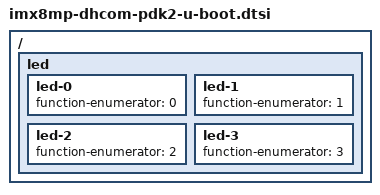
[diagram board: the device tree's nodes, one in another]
// SPDX-License-Identifier: (GPL-2.0+ OR MIT)
/*
 * Copyright (C) 2022 Marek Vasut <marex@denx.de>
 */

#include "imx8mp-dhcom-u-boot.dtsi"

/ {
	led {
		led-0 {
			function-enumerator = <0>;
		};

		led-1 {
			function-enumerator = <1>;
		};

		led-2 {
			function-enumerator = <2>;
		};

		led-3 {
			function-enumerator = <3>;
		};
	};
};
